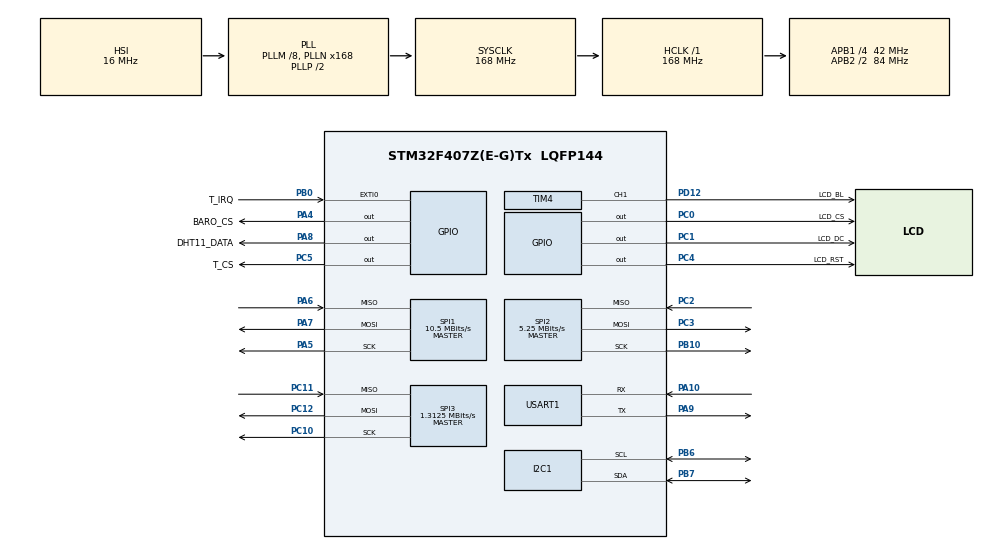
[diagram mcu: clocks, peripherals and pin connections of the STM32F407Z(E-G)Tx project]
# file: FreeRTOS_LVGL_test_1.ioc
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Dma.Request0=SPI1_TX
Dma.SPI1_TX.0.Direction=DMA_MEMORY_TO_PERIPH
Dma.SPI1_TX.0.FIFOMode=DMA_FIFOMODE_DISABLE
Dma.SPI1_TX.0.Instance=DMA2_Stream3
Dma.SPI1_TX.0.MemDataAlignment=DMA_MDATAALIGN_BYTE
Dma.SPI1_TX.0.MemInc=DMA_MINC_ENABLE
Dma.SPI1_TX.0.Mode=DMA_NORMAL
Dma.SPI1_TX.0.PeriphDataAlignment=DMA_PDATAALIGN_BYTE
Dma.SPI1_TX.0.PeriphInc=DMA_PINC_DISABLE
Dma.SPI1_TX.0.Priority=DMA_PRIORITY_VERY_HIGH
FREERTOS.Mutexes01=spi1Mutex,Dynamic,NULL,Available
FREERTOS.Queues01=mympu6050Queue,16,32,1,Dynamic,NULL,NULL
FREERTOS.Tasks01=defaultTask,24,128,StartDefaultTask,Default,NULL,Dynamic,NULL,NULL;myLVGLTask,32,2048,StartLVGLTask,As external,NULL,Dynamic,NULL,NULL;myMS5611Task,24,512,StartMS5611Task,As external,NULL,Dynamic,NULL,NULL;myDHT11Task,8,128,StartDHT11Task,As external,NULL,Dynamic,NULL,NULL;myMPU6050Task,40,512,StartMPU6050Task,As external,NULL,Dynamic,NULL,NULL;mympuprintfTask,8,1024,StartmpuprintfTask,As external,NULL,Dynamic,NULL,NULL;myRTCTask,16,256,StartRTCTask,As external,NULL,Dynamic,NULL,NULL;myTouchTask,32,512,StartTouchTask,As external,NULL,Dynamic,NULL,NULL
FREERTOS.configTOTAL_HEAP_SIZE=24576
I2C1.I2C_Mode=I2C_Fast
Mcu.Family=STM32F4
Mcu.Name=STM32F407Z(E-G)Tx
Mcu.Package=LQFP144
NVIC.DMA2_Stream3_IRQn=true\:5\:0\:false\:false\:true\:true\:false\:true\:true
NVIC.EXTI0_IRQn=true\:5\:0\:true\:false\:true\:false\:true\:true\:true
NVIC.PriorityGroup=NVIC_PRIORITYGROUP_4
NVIC.TIM6_DAC_IRQn=true\:15\:0\:true\:false\:true\:false\:false\:true\:true
NVIC.TimeBase=TIM6_DAC_IRQn
NVIC.TimeBaseIP=TIM6
PA10.Mode=Asynchronous
PA10.Signal=USART1_RX
PA13.Mode=Serial_Wire
PA13.Signal=SYS_JTMS-SWDIO
PA14.Mode=Serial_Wire
PA14.Signal=SYS_JTCK-SWCLK
PA4.GPIO_Label=BARO_CS
PA4.GPIO_Speed=GPIO_SPEED_FREQ_VERY_HIGH
PA4.PinState=GPIO_PIN_SET
PA4.Signal=GPIO_Output
PA5.Mode=Full_Duplex_Master
PA5.Signal=SPI1_SCK
PA6.Mode=Full_Duplex_Master
PA6.Signal=SPI1_MISO
PA7.Mode=Full_Duplex_Master
PA7.Signal=SPI1_MOSI
PA8.GPIO_Label=DHT11_DATA 
PA8.GPIO_PuPd=GPIO_PULLUP
PA8.PinState=GPIO_PIN_SET
PA8.Signal=GPIO_Output
PA9.Mode=Asynchronous
PA9.Signal=USART1_TX
PB0.GPIO_Label=T_IRQ
PB0.GPIO_ModeDefaultEXTI=GPIO_MODE_IT_FALLING
PB0.GPIO_PuPd=GPIO_PULLUP
PB0.Signal=GPXTI0
PB10.Mode=Full_Duplex_Master
PB10.Signal=SPI2_SCK
PB6.Mode=I2C
PB6.Signal=I2C1_SCL
PB7.Mode=I2C
PB7.Signal=I2C1_SDA
PC0.GPIO_Label=LCD_CS
PC0.GPIO_Speed=GPIO_SPEED_FREQ_VERY_HIGH
PC0.PinState=GPIO_PIN_SET
PC0.Signal=GPIO_Output
PC1.GPIO_Label=LCD_DC
PC1.GPIO_Speed=GPIO_SPEED_FREQ_VERY_HIGH
PC1.Signal=GPIO_Output
PC10.Mode=Full_Duplex_Master
PC10.Signal=SPI3_SCK
PC11.Mode=Full_Duplex_Master
PC11.Signal=SPI3_MISO
PC12.Mode=Full_Duplex_Master
PC12.Signal=SPI3_MOSI
PC14-OSC32_IN.Mode=LSE-External-Oscillator
PC14-OSC32_IN.Signal=RCC_OSC32_IN
PC15-OSC32_OUT.Mode=LSE-External-Oscillator
PC15-OSC32_OUT.Signal=RCC_OSC32_OUT
PC2.Mode=Full_Duplex_Master
PC2.Signal=SPI2_MISO
PC3.Mode=Full_Duplex_Master
PC3.Signal=SPI2_MOSI
PC4.GPIO_Label=LCD_RST
PC4.GPIO_Speed=GPIO_SPEED_FREQ_VERY_HIGH
PC4.PinState=GPIO_PIN_SET
PC4.Signal=GPIO_Output
PC5.GPIO_Label=T_CS
PC5.GPIO_Speed=GPIO_SPEED_FREQ_VERY_HIGH
PC5.PinState=GPIO_PIN_SET
PC5.Signal=GPIO_Output
PD12.GPIO_Label=LCD_BL
PD12.GPIO_Speed=GPIO_SPEED_FREQ_VERY_HIGH
PD12.Signal=S_TIM4_CH1
PH0-OSC_IN.Mode=HSE-External-Oscillator
PH0-OSC_IN.Signal=RCC_OSC_IN
PH1-OSC_OUT.Mode=HSE-External-Oscillator
PH1-OSC_OUT.Signal=RCC_OSC_OUT
ProjectManager.HeapSize=0x200
ProjectManager.StackSize=0x400
ProjectManager.TargetToolchain=CMake
RCC.48MHZClocksFreq_Value=84000000
RCC.AHBFreq_Value=168000000
RCC.APB1CLKDivider=RCC_HCLK_DIV4
RCC.APB1Freq_Value=42000000
RCC.APB1TimFreq_Value=84000000
RCC.APB2CLKDivider=RCC_HCLK_DIV2
RCC.APB2Freq_Value=84000000
RCC.APB2TimFreq_Value=168000000
RCC.CortexFreq_Value=168000000
RCC.HCLKFreq_Value=168000000
RCC.HSE_VALUE=25000000
RCC.HSI_VALUE=16000000
RCC.PLLM=8
RCC.PLLN=168
RCC.RCC_RTC_Clock_SourceVirtual=RCC_RTCCLKSOURCE_LSE
RCC.SYSCLKFreq_VALUE=168000000
RCC.SYSCLKSource=RCC_SYSCLKSOURCE_PLLCLK
RCC.VCOOutputFreq_Value=336000000
RTC.Date=9
RTC.Hours=21
RTC.Month=RTC_MONTH_APRIL
RTC.WeekDay=RTC_WEEKDAY_THURSDAY
RTC.Year=26
SH.S_TIM4_CH1.0=TIM4_CH1,PWM Generation1 CH1
SPI1.BaudRatePrescaler=SPI_BAUDRATEPRESCALER_8
SPI1.CalculateBaudRate=10.5 MBits/s
SPI1.Direction=SPI_DIRECTION_2LINES
SPI1.Mode=SPI_MODE_MASTER
SPI1.VirtualType=VM_MASTER
SPI2.BaudRatePrescaler=SPI_BAUDRATEPRESCALER_8
SPI2.CalculateBaudRate=5.25 MBits/s
SPI2.Direction=SPI_DIRECTION_2LINES
SPI2.Mode=SPI_MODE_MASTER
SPI2.VirtualType=VM_MASTER
SPI3.BaudRatePrescaler=SPI_BAUDRATEPRESCALER_32
SPI3.CalculateBaudRate=1.3125 MBits/s
SPI3.Direction=SPI_DIRECTION_2LINES
SPI3.Mode=SPI_MODE_MASTER
SPI3.VirtualType=VM_MASTER
TIM4.Channel-PWM\ Generation1\ CH1=TIM_CHANNEL_1
TIM4.Pulse-PWM\ Generation1\ CH1=100
USART1.VirtualMode=VM_ASYNC
VP_FREERTOS_VS_CMSIS_V2.Mode=CMSIS_V2
VP_RTC_VS_RTC_Activate.Mode=RTC_Enabled
VP_RTC_VS_RTC_Calendar.Mode=RTC_Calendar
VP_SYS_VS_tim6.Mode=TIM6
VP_TIM4_VS_ClockSourceINT.Mode=Internal
board=custom

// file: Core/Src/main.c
/* USER CODE BEGIN Header */
/**
  ******************************************************************************
  * @file           : main.c
  * @brief          : Main program body
  ******************************************************************************
  * @attention
  *
  * Copyright (c) 2026 STMicroelectronics.
  * All rights reserved.
  *
  * This software is licensed under terms that can be found in the LICENSE file
  * in the root directory of this software component.
  * If no LICENSE file comes with this software, it is provided AS-IS.
  *
  ******************************************************************************
  */
/* USER CODE END Header */
#include "main.h"
#include "cmsis_os.h"
#include "dma.h"
#include "i2c.h"
#include "rtc.h"
#include "spi.h"
#include "tim.h"
#include "usart.h"
#include "gpio.h"

void SystemClock_Config(void);
void MX_FREERTOS_Init(void);

int main(void)
{

  /* MCU Configuration--------------------------------------------------------*/

  /* Reset of all peripherals, Initializes the Flash interface and the Systick. */
  HAL_Init();

  /* Configure the system clock */
  SystemClock_Config();

  /* Initialize all configured peripherals */
  MX_GPIO_Init();
  MX_DMA_Init();
  MX_USART1_UART_Init();
  MX_SPI1_Init();
  MX_SPI2_Init();
  MX_TIM4_Init();
  MX_SPI3_Init();
  MX_I2C1_Init();
  MX_RTC_Init();

  /* Init scheduler */
  osKernelInitialize();  /* Call init function for freertos objects (in cmsis_os2.c) */
  MX_FREERTOS_Init();

  /* Start scheduler */
  osKernelStart();

  /* We should never get here as control is now taken by the scheduler */

  /* Infinite loop */
  while (1)
  {

  }
}

void SystemClock_Config(void)
{
  RCC_OscInitTypeDef RCC_OscInitStruct = {0};
  RCC_ClkInitTypeDef RCC_ClkInitStruct = {0};

  /** Configure the main internal regulator output voltage
  */
  __HAL_RCC_PWR_CLK_ENABLE();
  __HAL_PWR_VOLTAGESCALING_CONFIG(PWR_REGULATOR_VOLTAGE_SCALE1);

  /** Initializes the RCC Oscillators according to the specified parameters
  * in the RCC_OscInitTypeDef structure.
  */
  RCC_OscInitStruct.OscillatorType = RCC_OSCILLATORTYPE_HSI|RCC_OSCILLATORTYPE_LSE;
  RCC_OscInitStruct.LSEState = RCC_LSE_ON;
  RCC_OscInitStruct.HSIState = RCC_HSI_ON;
  RCC_OscInitStruct.HSICalibrationValue = RCC_HSICALIBRATION_DEFAULT;
  RCC_OscInitStruct.PLL.PLLState = RCC_PLL_ON;
  RCC_OscInitStruct.PLL.PLLSource = RCC_PLLSOURCE_HSI;
  RCC_OscInitStruct.PLL.PLLM = 8;
  RCC_OscInitStruct.PLL.PLLN = 168;
  RCC_OscInitStruct.PLL.PLLP = RCC_PLLP_DIV2;
  RCC_OscInitStruct.PLL.PLLQ = 4;
  if (HAL_RCC_OscConfig(&RCC_OscInitStruct) != HAL_OK)
  {
    Error_Handler();
  }

  /** Initializes the CPU, AHB and APB buses clocks
  */
  RCC_ClkInitStruct.ClockType = RCC_CLOCKTYPE_HCLK|RCC_CLOCKTYPE_SYSCLK
                              |RCC_CLOCKTYPE_PCLK1|RCC_CLOCKTYPE_PCLK2;
  RCC_ClkInitStruct.SYSCLKSource = RCC_SYSCLKSOURCE_PLLCLK;
  RCC_ClkInitStruct.AHBCLKDivider = RCC_SYSCLK_DIV1;
  RCC_ClkInitStruct.APB1CLKDivider = RCC_HCLK_DIV4;
  RCC_ClkInitStruct.APB2CLKDivider = RCC_HCLK_DIV2;

  if (HAL_RCC_ClockConfig(&RCC_ClkInitStruct, FLASH_LATENCY_5) != HAL_OK)
  {
    Error_Handler();
  }
}

void HAL_TIM_PeriodElapsedCallback(TIM_HandleTypeDef *htim)
{
  if (htim->Instance == TIM6)
  {
    HAL_IncTick();
  }
}

void Error_Handler(void)
{
  __disable_irq();
  while (1)
  {
  }
}

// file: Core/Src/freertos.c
/* USER CODE BEGIN Header */
/**
  ******************************************************************************
  * File Name          : freertos.c
  * Description        : Code for freertos applications
  ******************************************************************************
  * @attention
  *
  * Copyright (c) 2026 STMicroelectronics.
  * All rights reserved.
  *
  * This software is licensed under terms that can be found in the LICENSE file
  * in the root directory of this software component.
  * If no LICENSE file comes with this software, it is provided AS-IS.
  *
  ******************************************************************************
  */
/* USER CODE END Header */

#include "FreeRTOS.h"
#include "task.h"
#include "main.h"
#include "cmsis_os.h"

/* USER CODE BEGIN Includes */
#include "st7789.h"
#include "MS5611Task.h"
#include "i2c.h"
#include "spi.h"
#include "touch_task.h"

/* USER CODE END Includes */

/* Definitions for defaultTask */
osThreadId_t defaultTaskHandle;
const osThreadAttr_t defaultTask_attributes = {
  .name = "defaultTask",
  .stack_size = 128 * 4,
  .priority = (osPriority_t) osPriorityNormal,
};
/* Definitions for myLVGLTask */
osThreadId_t myLVGLTaskHandle;
const osThreadAttr_t myLVGLTask_attributes = {
  .name = "myLVGLTask",
  .stack_size = 2048 * 4,
  .priority = (osPriority_t) osPriorityAboveNormal,
};
/* Definitions for myMS5611Task */
osThreadId_t myMS5611TaskHandle;
const osThreadAttr_t myMS5611Task_attributes = {
  .name = "myMS5611Task",
  .stack_size = 512 * 4,
  .priority = (osPriority_t) osPriorityNormal,
};
/* Definitions for myDHT11Task */
osThreadId_t myDHT11TaskHandle;
const osThreadAttr_t myDHT11Task_attributes = {
  .name = "myDHT11Task",
  .stack_size = 128 * 4,
  .priority = (osPriority_t) osPriorityLow,
};
/* Definitions for myMPU6050Task */
osThreadId_t myMPU6050TaskHandle;
const osThreadAttr_t myMPU6050Task_attributes = {
  .name = "myMPU6050Task",
  .stack_size = 512 * 4,
  .priority = (osPriority_t) osPriorityHigh,
};
/* Definitions for mympuprintfTask */
osThreadId_t mympuprintfTaskHandle;
const osThreadAttr_t mympuprintfTask_attributes = {
  .name = "mympuprintfTask",
  .stack_size = 1024 * 4,
  .priority = (osPriority_t) osPriorityLow,
};
/* Definitions for myRTCTask */
osThreadId_t myRTCTaskHandle;
const osThreadAttr_t myRTCTask_attributes = {
  .name = "myRTCTask",
  .stack_size = 256 * 4,
  .priority = (osPriority_t) osPriorityBelowNormal,
};
/* Definitions for myTouchTask */
osThreadId_t myTouchTaskHandle;
const osThreadAttr_t myTouchTask_attributes = {
  .name = "myTouchTask",
  .stack_size = 512 * 4,
  .priority = (osPriority_t) osPriorityAboveNormal,
};
/* Definitions for mympu6050Queue */
osMessageQueueId_t mympu6050QueueHandle;
const osMessageQueueAttr_t mympu6050Queue_attributes = {
  .name = "mympu6050Queue"
};
/* Definitions for spi1Mutex */
osMutexId_t spi1MutexHandle;
const osMutexAttr_t spi1Mutex_attributes = {
  .name = "spi1Mutex"
};

void StartDefaultTask(void *argument);
extern void StartLVGLTask(void *argument);
extern void StartMS5611Task(void *argument);
extern void StartDHT11Task(void *argument);
extern void StartMPU6050Task(void *argument);
extern void StartmpuprintfTask(void *argument);
extern void StartRTCTask(void *argument);
extern void StartTouchTask(void *argument);

void MX_FREERTOS_Init(void); /* (MISRA C 2004 rule 8.1) */

void MX_FREERTOS_Init(void) {
  /* Create the mutex(es) */
  /* creation of spi1Mutex */
  spi1MutexHandle = osMutexNew(&spi1Mutex_attributes);

  /* USER CODE BEGIN RTOS_SEMAPHORES */
  /* add semaphores, ... */
  {
    const osSemaphoreAttr_t touchSemAttr = {0};
    g_touch_sem = osSemaphoreNew(1U, 0U, &touchSemAttr);
  }
  /* USER CODE END RTOS_SEMAPHORES */

  /* Create the queue(s) */
  /* creation of mympu6050Queue */
  mympu6050QueueHandle = osMessageQueueNew (16, 32, &mympu6050Queue_attributes);

  /* Create the thread(s) */
  /* creation of defaultTask */
  defaultTaskHandle = osThreadNew(StartDefaultTask, NULL, &defaultTask_attributes);

  /* creation of myLVGLTask */
  myLVGLTaskHandle = osThreadNew(StartLVGLTask, NULL, &myLVGLTask_attributes);

  /* creation of myMS5611Task */
  myMS5611TaskHandle = osThreadNew(StartMS5611Task, NULL, &myMS5611Task_attributes);

  /* creation of myDHT11Task */
  myDHT11TaskHandle = osThreadNew(StartDHT11Task, NULL, &myDHT11Task_attributes);

  /* creation of myMPU6050Task */
  myMPU6050TaskHandle = osThreadNew(StartMPU6050Task, NULL, &myMPU6050Task_attributes);

  /* creation of mympuprintfTask */
  mympuprintfTaskHandle = osThreadNew(StartmpuprintfTask, NULL, &mympuprintfTask_attributes);

  /* creation of myRTCTask */
  myRTCTaskHandle = osThreadNew(StartRTCTask, NULL, &myRTCTask_attributes);

  /* creation of myTouchTask */
  myTouchTaskHandle = osThreadNew(StartTouchTask, NULL, &myTouchTask_attributes);

}

void StartDefaultTask(void *argument)
{
  for(;;)
  {
    osDelay(1);
  }
}
